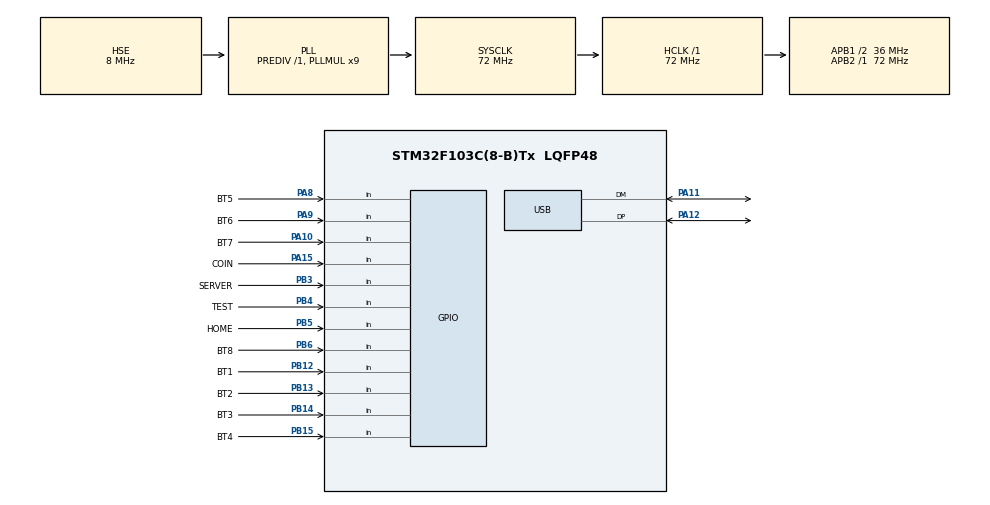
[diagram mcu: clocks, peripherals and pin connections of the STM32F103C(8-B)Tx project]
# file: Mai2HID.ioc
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Mcu.Family=STM32F1
Mcu.Name=STM32F103C(8-B)Tx
Mcu.Package=LQFP48
NVIC.PriorityGroup=NVIC_PRIORITYGROUP_4
NVIC.USB_LP_CAN1_RX0_IRQn=true\:0\:0\:false\:false\:true\:false\:true\:true
PA10.GPIO_Label=BT7
PA10.GPIO_PuPd=GPIO_PULLUP
PA10.Signal=GPIO_Input
PA11.Mode=Device
PA11.Signal=USB_DM
PA12.Mode=Device
PA12.Signal=USB_DP
PA15.GPIO_Label=COIN
PA15.GPIO_PuPd=GPIO_PULLUP
PA15.Signal=GPIO_Input
PA8.GPIO_Label=BT5
PA8.GPIO_PuPd=GPIO_PULLUP
PA8.Signal=GPIO_Input
PA9.GPIO_Label=BT6
PA9.GPIO_PuPd=GPIO_PULLUP
PA9.Signal=GPIO_Input
PB12.GPIO_Label=BT1
PB12.GPIO_PuPd=GPIO_PULLUP
PB12.Signal=GPIO_Input
PB13.GPIO_Label=BT2
PB13.GPIO_PuPd=GPIO_PULLUP
PB13.Signal=GPIO_Input
PB14.GPIO_Label=BT3
PB14.GPIO_PuPd=GPIO_PULLUP
PB14.Signal=GPIO_Input
PB15.GPIO_Label=BT4
PB15.GPIO_PuPd=GPIO_PULLUP
PB15.Signal=GPIO_Input
PB3.GPIO_Label=SERVER
PB3.GPIO_PuPd=GPIO_PULLUP
PB3.Signal=GPIO_Input
PB4.GPIO_Label=TEST
PB4.GPIO_PuPd=GPIO_PULLUP
PB4.Signal=GPIO_Input
PB5.GPIO_Label=HOME
PB5.GPIO_PuPd=GPIO_PULLUP
PB5.Signal=GPIO_Input
PB6.GPIO_Label=BT8
PB6.GPIO_PuPd=GPIO_PULLUP
PB6.Signal=GPIO_Input
PD0-OSC_IN.Mode=HSE-External-Oscillator
PD0-OSC_IN.Signal=RCC_OSC_IN
PD1-OSC_OUT.Mode=HSE-External-Oscillator
PD1-OSC_OUT.Signal=RCC_OSC_OUT
ProjectManager.HeapSize=0x200
ProjectManager.StackSize=0x400
ProjectManager.TargetToolchain=STM32CubeIDE
RCC.AHBFreq_Value=72000000
RCC.APB1CLKDivider=RCC_HCLK_DIV2
RCC.APB1Freq_Value=36000000
RCC.APB1TimFreq_Value=72000000
RCC.APB2Freq_Value=72000000
RCC.APB2TimFreq_Value=72000000
RCC.HCLKFreq_Value=72000000
RCC.PLLMUL=RCC_PLL_MUL9
RCC.SYSCLKFreq_VALUE=72000000
RCC.SYSCLKSource=RCC_SYSCLKSOURCE_PLLCLK
RCC.USBFreq_Value=48000000
RCC.USBPrescaler=RCC_USBCLKSOURCE_PLL_DIV1_5
USB_DEVICE.CLASS_NAME_FS=CUSTOM_HID
USB_DEVICE.VirtualMode=CustomHid
USB_DEVICE.VirtualModeFS=Custom_Hid_FS
VP_SYS_VS_ND.Mode=No_Debug
VP_USB_DEVICE_VS_USB_DEVICE_CUSTOM_HID_FS.Mode=CUSTOM_HID_FS
board=custom

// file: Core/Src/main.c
/* USER CODE BEGIN Header */
/**
  ******************************************************************************
  * @file           : main.c
  * @brief          : Main program body
  ******************************************************************************
  * @attention
  *
  * Copyright (c) 2025 STMicroelectronics.
  * All rights reserved.
  *
  * This software is licensed under terms that can be found in the LICENSE file
  * in the root directory of this software component.
  * If no LICENSE file comes with this software, it is provided AS-IS.
  *
  ******************************************************************************
  */
/* USER CODE END Header */
#include "main.h"
#include "usb_device.h"
#include "gpio.h"

void SystemClock_Config(void);

/* USER CODE BEGIN 0 */
	int a=0;
/* USER CODE END 0 */

int main(void)
{

  /* MCU Configuration--------------------------------------------------------*/

  /* Reset of all peripherals, Initializes the Flash interface and the Systick. */
  HAL_Init();

  /* Configure the system clock */
  SystemClock_Config();

  /* Initialize all configured peripherals */
  MX_GPIO_Init();
  MX_USB_DEVICE_Init();

  /* Infinite loop */
  /* USER CODE BEGIN WHILE */
  while (1)
  {
	  if(HAL_GPIO_ReadPin(BT1_GPIO_Port, BT1_Pin)==BT_TRIG_STATE){HIDSend(61);}if(HAL_GPIO_ReadPin(BT1_GPIO_Port, BT1_Pin)!=BT_TRIG_STATE){HIDSend(62);}//W
	  if(HAL_GPIO_ReadPin(BT2_GPIO_Port, BT2_Pin)==BT_TRIG_STATE){HIDSend(25);}if(HAL_GPIO_ReadPin(BT2_GPIO_Port, BT2_Pin)!=BT_TRIG_STATE){HIDSend(26);}//E
	  if(HAL_GPIO_ReadPin(BT3_GPIO_Port, BT3_Pin)==BT_TRIG_STATE){HIDSend(23);}if(HAL_GPIO_ReadPin(BT3_GPIO_Port, BT3_Pin)!=BT_TRIG_STATE){HIDSend(24);}//D
	  if(HAL_GPIO_ReadPin(BT4_GPIO_Port, BT4_Pin)==BT_TRIG_STATE){HIDSend(21);}if(HAL_GPIO_ReadPin(BT4_GPIO_Port, BT4_Pin)!=BT_TRIG_STATE){HIDSend(22);}//C
	  if(HAL_GPIO_ReadPin(BT5_GPIO_Port, BT5_Pin)==BT_TRIG_STATE){HIDSend(63);}if(HAL_GPIO_ReadPin(BT5_GPIO_Port, BT5_Pin)!=BT_TRIG_STATE){HIDSend(64);}//X
	  if(HAL_GPIO_ReadPin(BT6_GPIO_Port, BT6_Pin)==BT_TRIG_STATE){HIDSend(67);}if(HAL_GPIO_ReadPin(BT6_GPIO_Port, BT6_Pin)!=BT_TRIG_STATE){HIDSend(68);}//Z
	  if(HAL_GPIO_ReadPin(BT7_GPIO_Port, BT7_Pin)==BT_TRIG_STATE){HIDSend(17);}if(HAL_GPIO_ReadPin(BT7_GPIO_Port, BT7_Pin)!=BT_TRIG_STATE){HIDSend(18);}//A
	  if(HAL_GPIO_ReadPin(BT8_GPIO_Port, BT8_Pin)==BT_TRIG_STATE){HIDSend(49);}if(HAL_GPIO_ReadPin(BT8_GPIO_Port, BT8_Pin)!=BT_TRIG_STATE){HIDSend(50);}//Q
	  if(HAL_GPIO_ReadPin(TEST_GPIO_Port, TEST_Pin)==OUTHER_KET_TRIG_STATE){HIDSend(85);}if(HAL_GPIO_ReadPin(TEST_GPIO_Port, TEST_Pin)!=OUTHER_KET_TRIG_STATE){HIDSend(86);}//上9
	  if(HAL_GPIO_ReadPin(SERVER_GPIO_Port, SERVER_Pin)==OUTHER_KET_TRIG_STATE){HIDSend(83);}if(HAL_GPIO_ReadPin(SERVER_GPIO_Port, SERVER_Pin)!=OUTHER_KET_TRIG_STATE){HIDSend(84);}//上8
	  if(HAL_GPIO_ReadPin(COIN_GPIO_Port, COIN_Pin)==OUTHER_KET_TRIG_STATE){HIDSend(73);}if(HAL_GPIO_ReadPin(COIN_GPIO_Port, COIN_Pin)!=OUTHER_KET_TRIG_STATE){HIDSend(74);}//NULL
	  if(HAL_GPIO_ReadPin(HOME_GPIO_Port, HOME_Pin)==OUTHER_KET_TRIG_STATE){HIDSend(157);}if(HAL_GPIO_ReadPin(HOME_GPIO_Port, HOME_Pin)!=OUTHER_KET_TRIG_STATE){HIDSend(158);}//HOME

    /* USER CODE END WHILE */

  }
}

void SystemClock_Config(void)
{
  RCC_OscInitTypeDef RCC_OscInitStruct = {0};
  RCC_ClkInitTypeDef RCC_ClkInitStruct = {0};
  RCC_PeriphCLKInitTypeDef PeriphClkInit = {0};

  /** Initializes the RCC Oscillators according to the specified parameters
  * in the RCC_OscInitTypeDef structure.
  */
  RCC_OscInitStruct.OscillatorType = RCC_OSCILLATORTYPE_HSE;
  RCC_OscInitStruct.HSEState = RCC_HSE_ON;
  RCC_OscInitStruct.HSEPredivValue = RCC_HSE_PREDIV_DIV1;
  RCC_OscInitStruct.HSIState = RCC_HSI_ON;
  RCC_OscInitStruct.PLL.PLLState = RCC_PLL_ON;
  RCC_OscInitStruct.PLL.PLLSource = RCC_PLLSOURCE_HSE;
  RCC_OscInitStruct.PLL.PLLMUL = RCC_PLL_MUL9;
  if (HAL_RCC_OscConfig(&RCC_OscInitStruct) != HAL_OK)
  {
    Error_Handler();
  }

  /** Initializes the CPU, AHB and APB buses clocks
  */
  RCC_ClkInitStruct.ClockType = RCC_CLOCKTYPE_HCLK|RCC_CLOCKTYPE_SYSCLK
                              |RCC_CLOCKTYPE_PCLK1|RCC_CLOCKTYPE_PCLK2;
  RCC_ClkInitStruct.SYSCLKSource = RCC_SYSCLKSOURCE_PLLCLK;
  RCC_ClkInitStruct.AHBCLKDivider = RCC_SYSCLK_DIV1;
  RCC_ClkInitStruct.APB1CLKDivider = RCC_HCLK_DIV2;
  RCC_ClkInitStruct.APB2CLKDivider = RCC_HCLK_DIV1;

  if (HAL_RCC_ClockConfig(&RCC_ClkInitStruct, FLASH_LATENCY_2) != HAL_OK)
  {
    Error_Handler();
  }
  PeriphClkInit.PeriphClockSelection = RCC_PERIPHCLK_USB;
  PeriphClkInit.UsbClockSelection = RCC_USBCLKSOURCE_PLL_DIV1_5;
  if (HAL_RCCEx_PeriphCLKConfig(&PeriphClkInit) != HAL_OK)
  {
    Error_Handler();
  }
}

void Error_Handler(void)
{
  __disable_irq();
  while (1)
  {
  }
}
